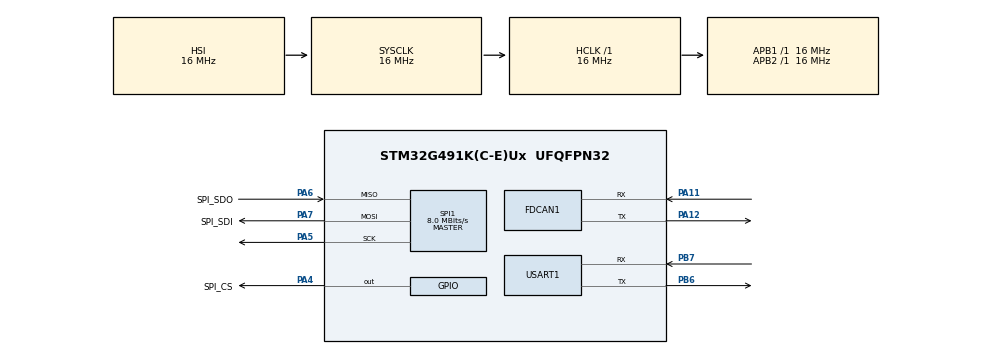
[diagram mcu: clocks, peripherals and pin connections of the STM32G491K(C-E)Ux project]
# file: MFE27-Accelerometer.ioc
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FDCAN1.CalculateBaudRateNominal=1000000
FDCAN1.CalculateTimeBitNominal=1000
FDCAN1.CalculateTimeQuantumNominal=62.5
FDCAN1.NominalPrescaler=1
FDCAN1.NominalTimeSeg1=13
FDCAN1.NominalTimeSeg2=2
FDCAN1.StdFiltersNbr=1
Mcu.Family=STM32G4
Mcu.Name=STM32G491K(C-E)Ux
Mcu.Package=UFQFPN32
NVIC.PriorityGroup=NVIC_PRIORITYGROUP_4
PA11.Mode=FDCAN_Activate
PA11.Signal=FDCAN1_RX
PA12.Mode=FDCAN_Activate
PA12.Signal=FDCAN1_TX
PA4.GPIO_Label=SPI_CS
PA4.Signal=GPIO_Output
PA5.Mode=Full_Duplex_Master
PA5.Signal=SPI1_SCK
PA6.GPIO_Label=SPI_SDO
PA6.Mode=Full_Duplex_Master
PA6.Signal=SPI1_MISO
PA7.GPIO_Label=SPI_SDI
PA7.Mode=Full_Duplex_Master
PA7.Signal=SPI1_MOSI
PB6.Mode=Asynchronous
PB6.Signal=USART1_TX
PB7.Mode=Asynchronous
PB7.Signal=USART1_RX
ProjectManager.HeapSize=0x200
ProjectManager.StackSize=0x400
ProjectManager.TargetToolchain=STM32CubeIDE
RCC.AHBFreq_Value=16000000
RCC.APB1Freq_Value=16000000
RCC.APB1TimFreq_Value=16000000
RCC.APB2Freq_Value=16000000
RCC.APB2TimFreq_Value=16000000
RCC.CortexFreq_Value=16000000
RCC.EXTERNAL_CLOCK_VALUE=12288000
RCC.HCLKFreq_Value=16000000
RCC.HSE_VALUE=8000000
RCC.HSI48_VALUE=48000000
RCC.HSI_VALUE=16000000
RCC.LSE_VALUE=32768
RCC.SYSCLKFreq_VALUE=16000000
RCC.VCOOutputFreq_Value=128000000
SPI1.CalculateBaudRate=8.0 MBits/s
SPI1.DataSize=SPI_DATASIZE_8BIT
SPI1.Direction=SPI_DIRECTION_2LINES
SPI1.Mode=SPI_MODE_MASTER
SPI1.VirtualType=VM_MASTER
USART1.VirtualMode-Asynchronous=VM_ASYNC
VP_SYS_VS_DBSignals.Mode=DisableDeadBatterySignals
board=custom

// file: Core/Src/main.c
/* USER CODE BEGIN Header */
/**
  ******************************************************************************
  * @file           : main.c
  * @brief          : Main program body
  ******************************************************************************
  * @attention
  *
  * Copyright (c) 2025 STMicroelectronics.
  * All rights reserved.
  *
  * This software is licensed under terms that can be found in the LICENSE file
  * in the root directory of this software component.
  * If no LICENSE file comes with this software, it is provided AS-IS.
  *
  ******************************************************************************
  */
/* USER CODE END Header */
#include "main.h"
#include "fdcan.h"
#include "spi.h"
#include "usart.h"
#include "gpio.h"

/* USER CODE BEGIN Includes */
#include "Board_Manager_Wrapper.h"
/* USER CODE END Includes */

void SystemClock_Config(void);

int main(void)
{

  /* MCU Configuration--------------------------------------------------------*/

  /* Reset of all peripherals, Initializes the Flash interface and the Systick. */
  HAL_Init();

  /* Configure the system clock */
  SystemClock_Config();

  /* Initialize all configured peripherals */
  MX_GPIO_Init();
  MX_FDCAN1_Init();
  MX_SPI1_Init();
  MX_USART1_UART_Init();
  /* USER CODE BEGIN 2 */
  uint32_t filterLowID = 0;
  uint32_t filterHighID = 1000;
  void* bm = BoardManager_create(filterLowID, filterHighID);
  if(!BoardManager_setup(bm)){
	  const char msg[] = "BoardManager setup FAILED\r\n";
	  HAL_UART_Transmit(&huart1, (uint8_t*)msg, sizeof(msg) - 1, HAL_MAX_DELAY);
  }

  /* USER CODE END 2 */

  /* Infinite loop */
  while (1)
  {
	  if(!BoardManager_readTransmitAccelData(bm)){
		  const char msg[] = "BoardManager readTransmit FAILED\r\n";
		  HAL_UART_Transmit(&huart1, (uint8_t*)msg, sizeof(msg) - 1, HAL_MAX_DELAY);
	  }
	  HAL_Delay(100);
  }
}

void SystemClock_Config(void)
{
  RCC_OscInitTypeDef RCC_OscInitStruct = {0};
  RCC_ClkInitTypeDef RCC_ClkInitStruct = {0};

  /** Configure the main internal regulator output voltage
  */
  HAL_PWREx_ControlVoltageScaling(PWR_REGULATOR_VOLTAGE_SCALE1);

  /** Initializes the RCC Oscillators according to the specified parameters
  * in the RCC_OscInitTypeDef structure.
  */
  RCC_OscInitStruct.OscillatorType = RCC_OSCILLATORTYPE_HSI;
  RCC_OscInitStruct.HSIState = RCC_HSI_ON;
  RCC_OscInitStruct.HSICalibrationValue = RCC_HSICALIBRATION_DEFAULT;
  RCC_OscInitStruct.PLL.PLLState = RCC_PLL_NONE;
  if (HAL_RCC_OscConfig(&RCC_OscInitStruct) != HAL_OK)
  {
    Error_Handler();
  }

  /** Initializes the CPU, AHB and APB buses clocks
  */
  RCC_ClkInitStruct.ClockType = RCC_CLOCKTYPE_HCLK|RCC_CLOCKTYPE_SYSCLK
                              |RCC_CLOCKTYPE_PCLK1|RCC_CLOCKTYPE_PCLK2;
  RCC_ClkInitStruct.SYSCLKSource = RCC_SYSCLKSOURCE_HSI;
  RCC_ClkInitStruct.AHBCLKDivider = RCC_SYSCLK_DIV1;
  RCC_ClkInitStruct.APB1CLKDivider = RCC_HCLK_DIV1;
  RCC_ClkInitStruct.APB2CLKDivider = RCC_HCLK_DIV1;

  if (HAL_RCC_ClockConfig(&RCC_ClkInitStruct, FLASH_LATENCY_0) != HAL_OK)
  {
    Error_Handler();
  }
}

void Error_Handler(void)
{
  __disable_irq();
  while (1)
  {
  }
}
